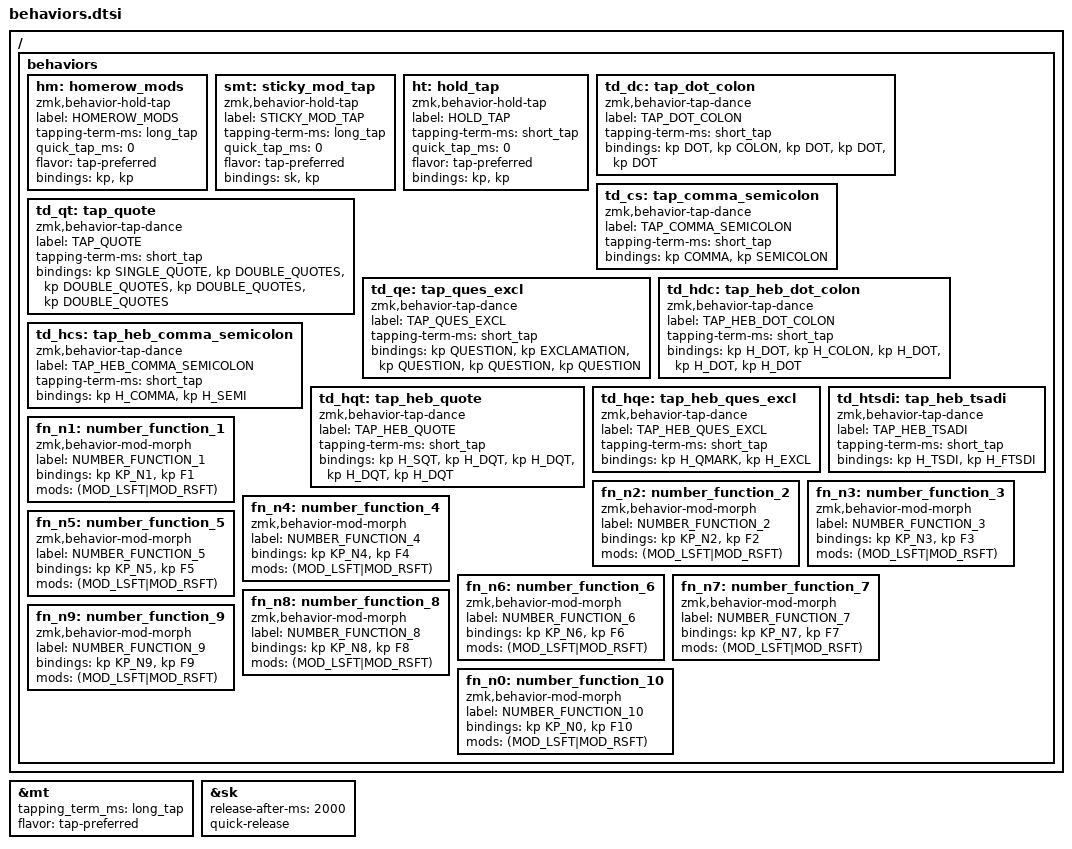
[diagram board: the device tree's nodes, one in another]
&mt {
    tapping_term_ms = <long_tap>;
    flavor = "tap-preferred";
};
&sk {
    release-after-ms = <2000>;
    quick-release;
};

/ {
    behaviors {
        hm: homerow_mods {
            compatible = "zmk,behavior-hold-tap";
            label = "HOMEROW_MODS";
            #binding-cells = <2>;
            tapping-term-ms = <long_tap>;
            quick_tap_ms = <0>;
            flavor = "tap-preferred";
            bindings = 
                <&kp>, 
                <&kp>;
        };
        smt: sticky_mod_tap {
            compatible = "zmk,behavior-hold-tap";
            label = "STICKY_MOD_TAP";
            #binding-cells = <2>;
            tapping-term-ms = <long_tap>;
            quick_tap_ms = <0>;
            flavor = "tap-preferred";
            bindings = 
                <&sk>, 
                <&kp>;
        };
        ht: hold_tap {
            compatible = "zmk,behavior-hold-tap";
            label = "HOLD_TAP";
            #binding-cells = <2>;
            tapping-term-ms = <short_tap>;
            quick_tap_ms = <0>;
            flavor = "tap-preferred";
            bindings = 
                <&kp>, 
                <&kp>;
        };
        // 1: Period "."; 2: Colon ":"; 3: Ellipsis "..."
        td_dc: tap_dot_colon {
            compatible = "zmk,behavior-tap-dance";
            label = "TAP_DOT_COLON";
            #binding-cells = <0>;
            tapping-term-ms = <short_tap>;
            bindings = 
                <&kp DOT>, 
                <&kp COLON>, 
                <&kp DOT &kp DOT &kp DOT>;
        };
        // 1: Comma ","; 2: Semicolon ";"
        td_cs: tap_comma_semicolon {
            compatible = "zmk,behavior-tap-dance";
            label = "TAP_COMMA_SEMICOLON";
            #binding-cells = <0>;
            tapping-term-ms = <short_tap>;
            bindings = 
                <&kp COMMA>, 
                <&kp SEMICOLON>;
        };
        // 1: Single quote "'"; 2: Double quote """; 3: Triple-double quote """""
        td_qt: tap_quote {
            compatible = "zmk,behavior-tap-dance";
            label = "TAP_QUOTE";
            #binding-cells = <0>;
            tapping-term-ms = <short_tap>;
            bindings = 
                <&kp SINGLE_QUOTE>, 
                <&kp DOUBLE_QUOTES>, 
                <&kp DOUBLE_QUOTES &kp DOUBLE_QUOTES &kp DOUBLE_QUOTES>;
        };
        // 1: Question mark "?"; 2: Exclamation mark "!"
        td_qe: tap_ques_excl {
            compatible = "zmk,behavior-tap-dance";
            label = "TAP_QUES_EXCL";
            #binding-cells = <0>;
            tapping-term-ms = <short_tap>;
            bindings = 
                <&kp QUESTION>, 
                <&kp EXCLAMATION>,
                <&kp QUESTION &kp QUESTION &kp QUESTION>;
        };
        // 1: Period "."; 2: Colon ":"; 3: Ellipsis "..."
        td_hdc: tap_heb_dot_colon {
            compatible = "zmk,behavior-tap-dance";
            label = "TAP_HEB_DOT_COLON";
            #binding-cells = <0>;
            tapping-term-ms = <short_tap>;
            bindings = 
                <&kp H_DOT>, 
                <&kp H_COLON>, 
                <&kp H_DOT &kp H_DOT &kp H_DOT>;
        };
        // 1: Comma ","; 2: Semicolon ";"
        td_hcs: tap_heb_comma_semicolon {
            compatible = "zmk,behavior-tap-dance";
            label = "TAP_HEB_COMMA_SEMICOLON";
            #binding-cells = <0>;
            tapping-term-ms = <short_tap>;
            bindings = 
                <&kp H_COMMA>, 
                <&kp H_SEMI>;
        };
        // 1: Single quote "'"; 2: Double quote """; 3: Triple-double quote """""
        td_hqt: tap_heb_quote {
            compatible = "zmk,behavior-tap-dance";
            label = "TAP_HEB_QUOTE";
            #binding-cells = <0>;
            tapping-term-ms = <short_tap>;
            bindings = 
                <&kp H_SQT>, 
                <&kp H_DQT>, 
                <&kp H_DQT &kp H_DQT &kp H_DQT>;
        };
        // 1: Question mark "?"; 2: Exclamation mark "!"
        td_hqe: tap_heb_ques_excl {
            compatible = "zmk,behavior-tap-dance";
            label = "TAP_HEB_QUES_EXCL";
            #binding-cells = <0>;
            tapping-term-ms = <short_tap>;
            bindings = 
                <&kp H_QMARK>, 
                <&kp H_EXCL>;
        };
        // 1: Question mark "?"; 2: Exclamation mark "!"
        td_htsdi: tap_heb_tsadi {
            compatible = "zmk,behavior-tap-dance";
            label = "TAP_HEB_TSADI";
            #binding-cells = <0>;
            tapping-term-ms = <short_tap>;
            bindings = 
                <&kp H_TSDI>, 
                <&kp H_FTSDI>;
        };
        // Number-Function Mod-Morph
        fn_n1: number_function_1 {
            compatible = "zmk,behavior-mod-morph";
            label = "NUMBER_FUNCTION_1";
            #binding-cells = <0>;
            bindings = 
                <&kp KP_N1>, 
                <&kp F1>;
            mods = <(MOD_LSFT|MOD_RSFT)>;
        };
        fn_n2: number_function_2 {
            compatible = "zmk,behavior-mod-morph";
            label = "NUMBER_FUNCTION_2";
            #binding-cells = <0>;
            bindings = 
                <&kp KP_N2>, 
                <&kp F2>;
            mods = <(MOD_LSFT|MOD_RSFT)>;
        };
        fn_n3: number_function_3 {
            compatible = "zmk,behavior-mod-morph";
            label = "NUMBER_FUNCTION_3";
            #binding-cells = <0>;
            bindings = 
                <&kp KP_N3>, 
                <&kp F3>;
            mods = <(MOD_LSFT|MOD_RSFT)>;
        };
        fn_n4: number_function_4 {
            compatible = "zmk,behavior-mod-morph";
            label = "NUMBER_FUNCTION_4";
            #binding-cells = <0>;
            bindings = 
                <&kp KP_N4>, 
                <&kp F4>;
            mods = <(MOD_LSFT|MOD_RSFT)>;
        };
        fn_n5: number_function_5 {
            compatible = "zmk,behavior-mod-morph";
            label = "NUMBER_FUNCTION_5";
            #binding-cells = <0>;
            bindings = 
                <&kp KP_N5>, 
                <&kp F5>;
            mods = <(MOD_LSFT|MOD_RSFT)>;
        };
        fn_n6: number_function_6 {
            compatible = "zmk,behavior-mod-morph";
            label = "NUMBER_FUNCTION_6";
            #binding-cells = <0>;
            bindings = 
                <&kp KP_N6>,
                <&kp F6>;
            mods = <(MOD_LSFT|MOD_RSFT)>;
        };
        fn_n7: number_function_7 {
            compatible = "zmk,behavior-mod-morph";
            label = "NUMBER_FUNCTION_7";
            #binding-cells = <0>;
            bindings = 
                <&kp KP_N7>,
                <&kp F7>;
            mods = <(MOD_LSFT|MOD_RSFT)>;
        };
        fn_n8: number_function_8 {
            compatible = "zmk,behavior-mod-morph";
            label = "NUMBER_FUNCTION_8";
            #binding-cells = <0>;
            bindings = 
                <&kp KP_N8>,
                <&kp F8>;
            mods = <(MOD_LSFT|MOD_RSFT)>;
        };
        fn_n9: number_function_9 {
            compatible = "zmk,behavior-mod-morph";
            label = "NUMBER_FUNCTION_9";
            #binding-cells = <0>;
            bindings = 
                <&kp KP_N9>, 
                <&kp F9>;
            mods = <(MOD_LSFT|MOD_RSFT)>;
        };
        fn_n0: number_function_10 {
            compatible = "zmk,behavior-mod-morph";
            label = "NUMBER_FUNCTION_10";
            #binding-cells = <0>;
            bindings = 
                <&kp KP_N0>,
                <&kp F10>;
            mods = <(MOD_LSFT|MOD_RSFT)>;
        };
    };
};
